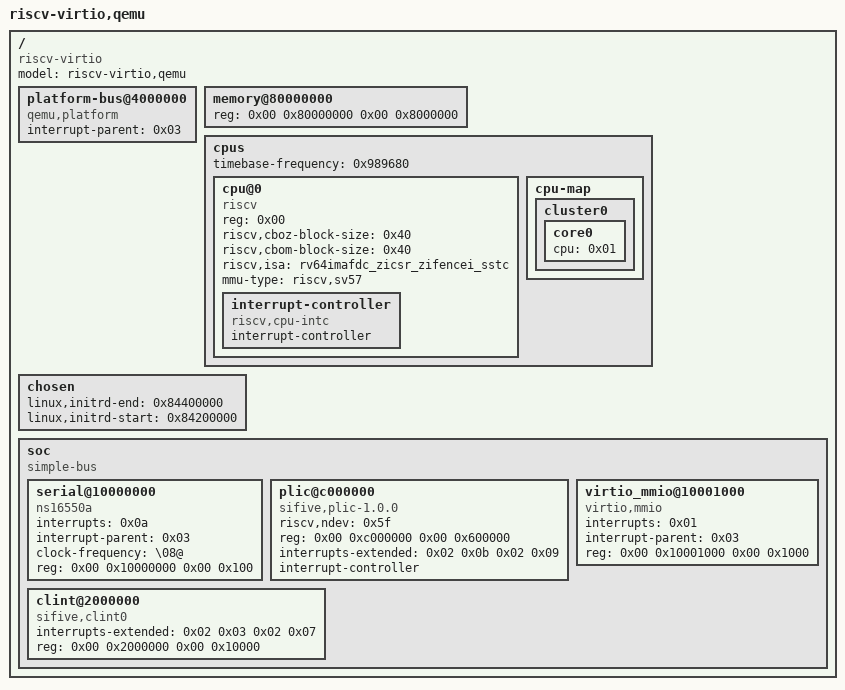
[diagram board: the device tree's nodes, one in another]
/dts-v1/;

/ {
	#address-cells = <0x02>;
	#size-cells = <0x02>;
	compatible = "riscv-virtio";
	model = "riscv-virtio,qemu";

	platform-bus@4000000 {
		interrupt-parent = <0x03>;
		ranges = <0x00 0x00 0x4000000 0x2000000>;
		#address-cells = <0x01>;
		#size-cells = <0x01>;
		compatible = "qemu,platform\0simple-bus";
	};

	memory@80000000 {
		device_type = "memory";
		reg = <0x00 0x80000000 0x00 0x8000000>;
	};

	cpus {
		#address-cells = <0x01>;
		#size-cells = <0x00>;
		timebase-frequency = <0x989680>;

		cpu@0 {
			phandle = <0x01>;
			device_type = "cpu";
			reg = <0x00>;
			status = "okay";
			compatible = "riscv";
			riscv,cboz-block-size = <0x40>;
			riscv,cbom-block-size = <0x40>;
			riscv,isa = "rv64imafdc_zicsr_zifencei_sstc";
			mmu-type = "riscv,sv57";

			interrupt-controller {
				#interrupt-cells = <0x01>;
				interrupt-controller;
				compatible = "riscv,cpu-intc";
				phandle = <0x02>;
			};
		};

		cpu-map {

			cluster0 {

				core0 {
					cpu = <0x01>;
				};
			};
		};
	};

	chosen {
		linux,initrd-end = <0x84400000>;
		linux,initrd-start = <0x84200000>;
	};

	soc {
		#address-cells = <0x02>;
		#size-cells = <0x02>;
		compatible = "simple-bus";
		ranges;

		serial@10000000 {
			interrupts = <0x0a>;
			interrupt-parent = <0x03>;
			clock-frequency = "\08@";
			reg = <0x00 0x10000000 0x00 0x100>;
			compatible = "ns16550a";
		};

		plic@c000000 {
			phandle = <0x03>;
			riscv,ndev = <0x5f>;
			reg = <0x00 0xc000000 0x00 0x600000>;
			interrupts-extended = <0x02 0x0b 0x02 0x09>;
			interrupt-controller;
			compatible = "sifive,plic-1.0.0\0riscv,plic0";
			#address-cells = <0x00>;
			#interrupt-cells = <0x01>;
		};

		clint@2000000 {
			interrupts-extended = <0x02 0x03 0x02 0x07>;
			reg = <0x00 0x2000000 0x00 0x10000>;
			compatible = "sifive,clint0\0riscv,clint0";
		};

		virtio_mmio@10001000 {
			interrupts = <0x01>;
			interrupt-parent = <0x03>;
			reg = <0x00 0x10001000 0x00 0x1000>;
			compatible = "virtio,mmio";
		};
	};
};
